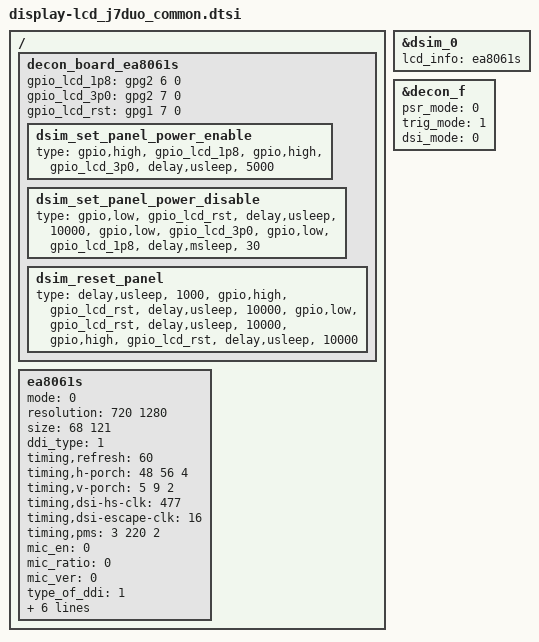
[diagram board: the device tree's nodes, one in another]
/*
 * SAMSUNG LCD Panel Device Tree Source
 *
 * Copyright (c) Samsung Electronics Co., Ltd.
 *		http://www.samsung.com
 *
 * This program is free software; you can redistribute it and/or modify
 * it under the terms of the GNU General Public License version 2 as
 * published by the Free Software Foundation.
*/

/ {
	decon_board_ea8061s: decon_board_ea8061s {
		gpio_lcd_1p8 = <&gpg2 6 0>;
		gpio_lcd_3p0 = <&gpg2 7 0>;
		gpio_lcd_rst = <&gpg1 7 0>;

		dsim_set_panel_power_enable {
			type =
			"gpio,high",	"gpio_lcd_1p8",
			"gpio,high",	"gpio_lcd_3p0",
			"delay,usleep",	"5000";
		};
		dsim_set_panel_power_disable {
			type =
			"gpio,low",	"gpio_lcd_rst",
			"delay,usleep",	"10000",
			"gpio,low",	"gpio_lcd_3p0",
			"gpio,low",	"gpio_lcd_1p8",
			"delay,msleep",	"30";
		};
		dsim_reset_panel {
			type =
			"delay,usleep",	"1000",
			"gpio,high",	"gpio_lcd_rst",
			"delay,usleep",	"10000",
			"gpio,low",	"gpio_lcd_rst",
			"delay,usleep",	"10000",
			"gpio,high",	"gpio_lcd_rst",
			"delay,usleep",	"10000";
		};
	};

	ea8061s: ea8061s {
		mode = <0>;
		resolution = <720 1280>;
		size = <68 121>;
		ddi_type = <1>;
		timing,refresh = <60>;
		/* HBP HFP HSW */
		timing,h-porch = <48 56 4>;
		/* VBP VFP VSW */
		timing,v-porch = <5 9 2>;
		timing,dsi-hs-clk = <477>;
		timing,dsi-escape-clk = <16>;
		timing,pms = <3 220 2>;
		mic_en = <0>;		/* 0: Disable, 1: Enable */
		mic_ratio = <0>;	/* 0: 1/2 mic, 1: 1/3 mic */
		mic_ver = <0>;		/* 0: mic v1.1, 1: v1.2, 2: v2.0 */
		type_of_ddi = <1>;	/* 0: Samsung Mobile, 1: MAGNA, 2: Normal(Etc) */
		dsc_en = <0>;		/* 0: Disable, 1: Enable */
		dsc_cnt = <0>;		/* used DSC count */
		dsc_slice_num = <0>;	/* count of dsc slice */
		data_lane = <4>;	/* number of using data lane */

		vt_compensation = <706>;	/* for difference between wordclk and vclk at video mode */
		decon_board = <&decon_board_ea8061s>;
	};
};

&dsim_0 {
	lcd_info = <&ea8061s>;
};

&decon_f {
	psr_mode = <0>;		/* 0: video mode, 1: DP command mode, 2: MIPI command mode */
	trig_mode = <1>;	/* 0: hw trigger, 1: sw trigger */
	dsi_mode = <0>;		/* 0: single dsi, 1: dual dsi */
};

